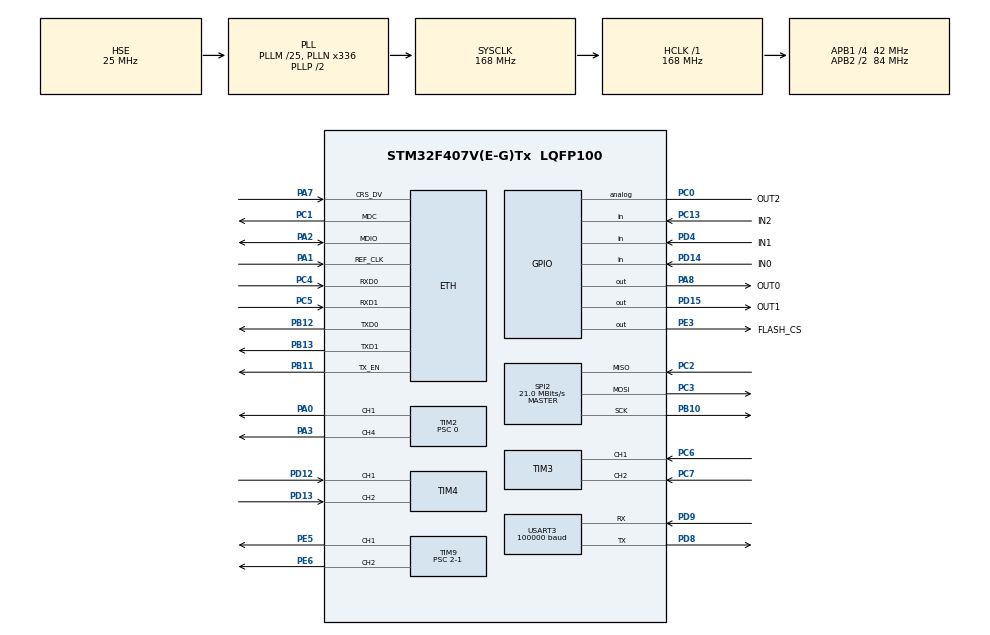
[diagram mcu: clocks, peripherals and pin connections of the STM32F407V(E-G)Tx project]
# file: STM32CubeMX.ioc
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Dma.Request0=USART3_RX
Dma.USART3_RX.0.Direction=DMA_PERIPH_TO_MEMORY
Dma.USART3_RX.0.FIFOMode=DMA_FIFOMODE_DISABLE
Dma.USART3_RX.0.Instance=DMA1_Stream1
Dma.USART3_RX.0.MemDataAlignment=DMA_MDATAALIGN_BYTE
Dma.USART3_RX.0.MemInc=DMA_MINC_ENABLE
Dma.USART3_RX.0.Mode=DMA_NORMAL
Dma.USART3_RX.0.PeriphDataAlignment=DMA_PDATAALIGN_BYTE
Dma.USART3_RX.0.PeriphInc=DMA_PINC_DISABLE
Dma.USART3_RX.0.Priority=DMA_PRIORITY_MEDIUM
ETH.MediaInterface=HAL_ETH_RMII_MODE
ETH.RxMode=ETH_RXINTERRUPT_MODE
Mcu.Family=STM32F4
Mcu.Name=STM32F407V(E-G)Tx
Mcu.Package=LQFP100
NVIC.DMA1_Stream1_IRQn=true\:5\:0\:true\:false\:true\:false\:true\:true
NVIC.ETH_IRQn=true\:7\:0\:true\:false\:true\:false\:true\:true
NVIC.PriorityGroup=NVIC_PRIORITYGROUP_4
NVIC.TIM3_IRQn=true\:4\:0\:true\:false\:true\:true\:true\:true
NVIC.TIM4_IRQn=true\:4\:0\:true\:false\:true\:true\:true\:true
NVIC.TIM7_IRQn=true\:4\:0\:true\:false\:true\:true\:true\:true
NVIC.TIM8_TRG_COM_TIM14_IRQn=true\:15\:0\:false\:false\:true\:false\:true\:true
NVIC.TimeBase=TIM8_TRG_COM_TIM14_IRQn
NVIC.TimeBaseIP=TIM14
NVIC.USART3_IRQn=true\:6\:0\:true\:false\:true\:true\:true\:true
PA0-WKUP.GPIO_Speed=GPIO_SPEED_FREQ_VERY_HIGH
PA0-WKUP.Signal=S_TIM2_CH1_ETR
PA1.Mode=RMII
PA1.Signal=ETH_REF_CLK
PA13.Mode=Serial_Wire
PA13.Signal=SYS_JTMS-SWDIO
PA14.Mode=Serial_Wire
PA14.Signal=SYS_JTCK-SWCLK
PA2.Mode=RMII
PA2.Signal=ETH_MDIO
PA3.GPIO_Speed=GPIO_SPEED_FREQ_VERY_HIGH
PA3.Signal=S_TIM2_CH4
PA7.Mode=RMII
PA7.Signal=ETH_CRS_DV
PA8.GPIO_Label=OUT0
PA8.Signal=GPIO_Output
PB10.Mode=Full_Duplex_Master
PB10.Signal=SPI2_SCK
PB11.Mode=RMII
PB11.Signal=ETH_TX_EN
PB12.Mode=RMII
PB12.Signal=ETH_TXD0
PB13.Mode=RMII
PB13.Signal=ETH_TXD1
PC0.GPIO_Label=OUT2
PC0.Signal=GPIO_Analog
PC1.Mode=RMII
PC1.Signal=ETH_MDC
PC13-ANTI_TAMP.GPIO_Label=IN2
PC13-ANTI_TAMP.Signal=GPIO_Input
PC14-OSC32_IN.Mode=LSE-External-Oscillator
PC14-OSC32_IN.Signal=RCC_OSC32_IN
PC15-OSC32_OUT.Mode=LSE-External-Oscillator
PC15-OSC32_OUT.Signal=RCC_OSC32_OUT
PC2.Mode=Full_Duplex_Master
PC2.Signal=SPI2_MISO
PC3.Mode=Full_Duplex_Master
PC3.Signal=SPI2_MOSI
PC4.Mode=RMII
PC4.Signal=ETH_RXD0
PC5.Mode=RMII
PC5.Signal=ETH_RXD1
PC6.GPIO_Speed=GPIO_SPEED_FREQ_HIGH
PC6.Signal=S_TIM3_CH1
PC7.GPIO_Speed=GPIO_SPEED_FREQ_HIGH
PC7.Signal=S_TIM3_CH2
PD12.Signal=S_TIM4_CH1
PD13.Signal=S_TIM4_CH2
PD14.GPIO_Label=IN0
PD14.Signal=GPIO_Input
PD15.GPIO_Label=OUT1
PD15.Signal=GPIO_Output
PD4.GPIO_Label=IN1
PD4.Signal=GPIO_Input
PD8.Mode=Asynchronous
PD8.Signal=USART3_TX
PD9.Mode=Asynchronous
PD9.Signal=USART3_RX
PE3.GPIO_Label=FLASH_CS
PE3.GPIO_Speed=GPIO_SPEED_FREQ_VERY_HIGH
PE3.Signal=GPIO_Output
PE5.GPIO_Speed=GPIO_SPEED_FREQ_VERY_HIGH
PE5.Signal=S_TIM9_CH1
PE6.GPIO_Speed=GPIO_SPEED_FREQ_VERY_HIGH
PE6.Signal=S_TIM9_CH2
PH0-OSC_IN.Mode=HSE-External-Oscillator
PH0-OSC_IN.Signal=RCC_OSC_IN
PH1-OSC_OUT.Mode=HSE-External-Oscillator
PH1-OSC_OUT.Signal=RCC_OSC_OUT
ProjectManager.HeapSize=0x200
ProjectManager.StackSize=0x200
ProjectManager.TargetToolchain=MDK-ARM V5.32
RCC.48MHZClocksFreq_Value=48000000
RCC.AHBFreq_Value=168000000
RCC.APB1CLKDivider=RCC_HCLK_DIV4
RCC.APB1Freq_Value=42000000
RCC.APB1TimFreq_Value=84000000
RCC.APB2CLKDivider=RCC_HCLK_DIV2
RCC.APB2Freq_Value=84000000
RCC.APB2TimFreq_Value=168000000
RCC.CortexFreq_Value=168000000
RCC.HCLKFreq_Value=168000000
RCC.HSE_VALUE=25000000
RCC.HSI_VALUE=16000000
RCC.PLLM=25
RCC.PLLN=336
RCC.PLLQ=7
RCC.PLLSourceVirtual=RCC_PLLSOURCE_HSE
RCC.SYSCLKFreq_VALUE=168000000
RCC.SYSCLKSource=RCC_SYSCLKSOURCE_PLLCLK
RCC.VCOOutputFreq_Value=336000000
SH.S_TIM2_CH1_ETR.0=TIM2_CH1,PWM Generation1 CH1
SH.S_TIM2_CH4.0=TIM2_CH4,PWM Generation4 CH4
SH.S_TIM3_CH1.0=TIM3_CH1,Encoder_Interface
SH.S_TIM3_CH2.0=TIM3_CH2,Encoder_Interface
SH.S_TIM4_CH1.0=TIM4_CH1,Encoder_Interface
SH.S_TIM4_CH2.0=TIM4_CH2,Encoder_Interface
SH.S_TIM9_CH1.0=TIM9_CH1,PWM Generation1 CH1
SH.S_TIM9_CH2.0=TIM9_CH2,PWM Generation2 CH2
SPI2.BaudRatePrescaler=SPI_BAUDRATEPRESCALER_2
SPI2.CalculateBaudRate=21.0 MBits/s
SPI2.Direction=SPI_DIRECTION_2LINES
SPI2.Mode=SPI_MODE_MASTER
SPI2.VirtualType=VM_MASTER
TIM2.Channel-PWM\ Generation1\ CH1=TIM_CHANNEL_1
TIM2.Channel-PWM\ Generation4\ CH4=TIM_CHANNEL_4
TIM2.Period=65535
TIM2.Prescaler=0
TIM3.EncoderMode=TIM_ENCODERMODE_TI12
TIM4.EncoderMode=TIM_ENCODERMODE_TI12
TIM4.IC1Polarity=TIM_ICPOLARITY_RISING
TIM7.Period=42000-1
TIM7.Prescaler=40-1
TIM9.Channel-PWM\ Generation1\ CH1=TIM_CHANNEL_1
TIM9.Channel-PWM\ Generation2\ CH2=TIM_CHANNEL_2
TIM9.Prescaler=2-1
USART3.BaudRate=100000
USART3.Mode=MODE_RX
USART3.Parity=PARITY_EVEN
USART3.StopBits=STOPBITS_2
USART3.VirtualMode=VM_ASYNC
USART3.WordLength=WORDLENGTH_9B
VP_SYS_VS_tim14.Mode=TIM14
VP_TIM7_VS_ClockSourceINT.Mode=Enable_Timer
board=custom

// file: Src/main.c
/* USER CODE BEGIN Header */
/**
  ******************************************************************************
  * @file           : main.c
  * @brief          : Main program body
  ******************************************************************************
  * @attention
  *
  * Copyright (c) 2025 STMicroelectronics.
  * All rights reserved.
  *
  * This software is licensed under terms that can be found in the LICENSE file
  * in the root directory of this software component.
  * If no LICENSE file comes with this software, it is provided AS-IS.
  *
  ******************************************************************************
  */
/* USER CODE END Header */
#include "main.h"
#include "string.h"

/* USER CODE BEGIN Includes */
#include "init.h"
/* USER CODE END Includes */

ETH_TxPacketConfig TxConfig;
ETH_DMADescTypeDef  DMARxDscrTab[ETH_RX_DESC_CNT]; /* Ethernet Rx DMA Descriptors */
ETH_DMADescTypeDef  DMATxDscrTab[ETH_TX_DESC_CNT]; /* Ethernet Tx DMA Descriptors */

ETH_HandleTypeDef heth;

SPI_HandleTypeDef hspi2;

TIM_HandleTypeDef htim2;
TIM_HandleTypeDef htim3;
TIM_HandleTypeDef htim4;
TIM_HandleTypeDef htim7;
TIM_HandleTypeDef htim9;

UART_HandleTypeDef huart3;
DMA_HandleTypeDef hdma_usart3_rx;

void SystemClock_Config(void);
static void MX_GPIO_Init(void);
static void MX_DMA_Init(void);
static void MX_ETH_Init(void);
static void MX_SPI2_Init(void);
static void MX_TIM3_Init(void);
static void MX_TIM9_Init(void);
static void MX_TIM2_Init(void);
static void MX_TIM4_Init(void);
static void MX_TIM7_Init(void);
static void MX_USART3_UART_Init(void);

int main(void)
{

  /* MCU Configuration--------------------------------------------------------*/

  /* Reset of all peripherals, Initializes the Flash interface and the Systick. */
  HAL_Init();

  /* Configure the system clock */
  SystemClock_Config();

  /* Initialize all configured peripherals */
  MX_GPIO_Init();
  MX_DMA_Init();
  MX_ETH_Init();
  MX_SPI2_Init();
  MX_TIM3_Init();
  MX_TIM9_Init();
  MX_TIM2_Init();
  MX_TIM4_Init();
  MX_TIM7_Init();
  MX_USART3_UART_Init();
  /* USER CODE BEGIN 2 */
	osKernelInitialize();
	System_Init();
	osKernelStart();
  /* USER CODE END 2 */

  /* Infinite loop */
  while (1)
  {

  }
}

void SystemClock_Config(void)
{
  RCC_OscInitTypeDef RCC_OscInitStruct = {0};
  RCC_ClkInitTypeDef RCC_ClkInitStruct = {0};

  /** Configure the main internal regulator output voltage
  */
  __HAL_RCC_PWR_CLK_ENABLE();
  __HAL_PWR_VOLTAGESCALING_CONFIG(PWR_REGULATOR_VOLTAGE_SCALE1);

  /** Initializes the RCC Oscillators according to the specified parameters
  * in the RCC_OscInitTypeDef structure.
  */
  RCC_OscInitStruct.OscillatorType = RCC_OSCILLATORTYPE_HSE;
  RCC_OscInitStruct.HSEState = RCC_HSE_ON;
  RCC_OscInitStruct.PLL.PLLState = RCC_PLL_ON;
  RCC_OscInitStruct.PLL.PLLSource = RCC_PLLSOURCE_HSE;
  RCC_OscInitStruct.PLL.PLLM = 25;
  RCC_OscInitStruct.PLL.PLLN = 336;
  RCC_OscInitStruct.PLL.PLLP = RCC_PLLP_DIV2;
  RCC_OscInitStruct.PLL.PLLQ = 7;
  if (HAL_RCC_OscConfig(&RCC_OscInitStruct) != HAL_OK)
  {
    Error_Handler();
  }

  /** Initializes the CPU, AHB and APB buses clocks
  */
  RCC_ClkInitStruct.ClockType = RCC_CLOCKTYPE_HCLK|RCC_CLOCKTYPE_SYSCLK
                              |RCC_CLOCKTYPE_PCLK1|RCC_CLOCKTYPE_PCLK2;
  RCC_ClkInitStruct.SYSCLKSource = RCC_SYSCLKSOURCE_PLLCLK;
  RCC_ClkInitStruct.AHBCLKDivider = RCC_SYSCLK_DIV1;
  RCC_ClkInitStruct.APB1CLKDivider = RCC_HCLK_DIV4;
  RCC_ClkInitStruct.APB2CLKDivider = RCC_HCLK_DIV2;

  if (HAL_RCC_ClockConfig(&RCC_ClkInitStruct, FLASH_LATENCY_5) != HAL_OK)
  {
    Error_Handler();
  }
}

static void MX_ETH_Init(void)
{

   static uint8_t MACAddr[6];

  heth.Instance = ETH;
  MACAddr[0] = 0x00;
  MACAddr[1] = 0x80;
  MACAddr[2] = 0xE1;
  MACAddr[3] = 0x00;
  MACAddr[4] = 0x00;
  MACAddr[5] = 0x00;
  heth.Init.MACAddr = &MACAddr[0];
  heth.Init.MediaInterface = HAL_ETH_RMII_MODE;
  heth.Init.TxDesc = DMATxDscrTab;
  heth.Init.RxDesc = DMARxDscrTab;
  heth.Init.RxBuffLen = 1524;

  if (HAL_ETH_Init(&heth) != HAL_OK)
  {
    Error_Handler();
  }

  memset(&TxConfig, 0 , sizeof(ETH_TxPacketConfig));
  TxConfig.Attributes = ETH_TX_PACKETS_FEATURES_CSUM | ETH_TX_PACKETS_FEATURES_CRCPAD;
  TxConfig.ChecksumCtrl = ETH_CHECKSUM_IPHDR_PAYLOAD_INSERT_PHDR_CALC;
  TxConfig.CRCPadCtrl = ETH_CRC_PAD_INSERT;

}

static void MX_SPI2_Init(void)
{

  /* SPI2 parameter configuration*/
  hspi2.Instance = SPI2;
  hspi2.Init.Mode = SPI_MODE_MASTER;
  hspi2.Init.Direction = SPI_DIRECTION_2LINES;
  hspi2.Init.DataSize = SPI_DATASIZE_8BIT;
  hspi2.Init.CLKPolarity = SPI_POLARITY_LOW;
  hspi2.Init.CLKPhase = SPI_PHASE_1EDGE;
  hspi2.Init.NSS = SPI_NSS_SOFT;
  hspi2.Init.BaudRatePrescaler = SPI_BAUDRATEPRESCALER_2;
  hspi2.Init.FirstBit = SPI_FIRSTBIT_MSB;
  hspi2.Init.TIMode = SPI_TIMODE_DISABLE;
  hspi2.Init.CRCCalculation = SPI_CRCCALCULATION_DISABLE;
  hspi2.Init.CRCPolynomial = 10;
  if (HAL_SPI_Init(&hspi2) != HAL_OK)
  {
    Error_Handler();
  }

}

static void MX_TIM2_Init(void)
{

  TIM_MasterConfigTypeDef sMasterConfig = {0};
  TIM_OC_InitTypeDef sConfigOC = {0};

  htim2.Instance = TIM2;
  htim2.Init.Prescaler = 0;
  htim2.Init.CounterMode = TIM_COUNTERMODE_UP;
  htim2.Init.Period = 65535;
  htim2.Init.ClockDivision = TIM_CLOCKDIVISION_DIV1;
  htim2.Init.AutoReloadPreload = TIM_AUTORELOAD_PRELOAD_DISABLE;
  if (HAL_TIM_PWM_Init(&htim2) != HAL_OK)
  {
    Error_Handler();
  }
  sMasterConfig.MasterOutputTrigger = TIM_TRGO_RESET;
  sMasterConfig.MasterSlaveMode = TIM_MASTERSLAVEMODE_DISABLE;
  if (HAL_TIMEx_MasterConfigSynchronization(&htim2, &sMasterConfig) != HAL_OK)
  {
    Error_Handler();
  }
  sConfigOC.OCMode = TIM_OCMODE_PWM1;
  sConfigOC.Pulse = 0;
  sConfigOC.OCPolarity = TIM_OCPOLARITY_HIGH;
  sConfigOC.OCFastMode = TIM_OCFAST_DISABLE;
  if (HAL_TIM_PWM_ConfigChannel(&htim2, &sConfigOC, TIM_CHANNEL_1) != HAL_OK)
  {
    Error_Handler();
  }
  if (HAL_TIM_PWM_ConfigChannel(&htim2, &sConfigOC, TIM_CHANNEL_4) != HAL_OK)
  {
    Error_Handler();
  }
  HAL_TIM_MspPostInit(&htim2);

}

static void MX_TIM3_Init(void)
{

  TIM_Encoder_InitTypeDef sConfig = {0};
  TIM_MasterConfigTypeDef sMasterConfig = {0};

  htim3.Instance = TIM3;
  htim3.Init.Prescaler = 0;
  htim3.Init.CounterMode = TIM_COUNTERMODE_UP;
  htim3.Init.Period = 65535;
  htim3.Init.ClockDivision = TIM_CLOCKDIVISION_DIV1;
  htim3.Init.AutoReloadPreload = TIM_AUTORELOAD_PRELOAD_DISABLE;
  sConfig.EncoderMode = TIM_ENCODERMODE_TI12;
  sConfig.IC1Polarity = TIM_ICPOLARITY_RISING;
  sConfig.IC1Selection = TIM_ICSELECTION_DIRECTTI;
  sConfig.IC1Prescaler = TIM_ICPSC_DIV1;
  sConfig.IC1Filter = 0;
  sConfig.IC2Polarity = TIM_ICPOLARITY_RISING;
  sConfig.IC2Selection = TIM_ICSELECTION_DIRECTTI;
  sConfig.IC2Prescaler = TIM_ICPSC_DIV1;
  sConfig.IC2Filter = 0;
  if (HAL_TIM_Encoder_Init(&htim3, &sConfig) != HAL_OK)
  {
    Error_Handler();
  }
  sMasterConfig.MasterOutputTrigger = TIM_TRGO_RESET;
  sMasterConfig.MasterSlaveMode = TIM_MASTERSLAVEMODE_DISABLE;
  if (HAL_TIMEx_MasterConfigSynchronization(&htim3, &sMasterConfig) != HAL_OK)
  {
    Error_Handler();
  }

}

static void MX_TIM4_Init(void)
{

  TIM_Encoder_InitTypeDef sConfig = {0};
  TIM_MasterConfigTypeDef sMasterConfig = {0};

  htim4.Instance = TIM4;
  htim4.Init.Prescaler = 0;
  htim4.Init.CounterMode = TIM_COUNTERMODE_UP;
  htim4.Init.Period = 65535;
  htim4.Init.ClockDivision = TIM_CLOCKDIVISION_DIV1;
  htim4.Init.AutoReloadPreload = TIM_AUTORELOAD_PRELOAD_DISABLE;
  sConfig.EncoderMode = TIM_ENCODERMODE_TI12;
  sConfig.IC1Polarity = TIM_ICPOLARITY_RISING;
  sConfig.IC1Selection = TIM_ICSELECTION_DIRECTTI;
  sConfig.IC1Prescaler = TIM_ICPSC_DIV1;
  sConfig.IC1Filter = 0;
  sConfig.IC2Polarity = TIM_ICPOLARITY_RISING;
  sConfig.IC2Selection = TIM_ICSELECTION_DIRECTTI;
  sConfig.IC2Prescaler = TIM_ICPSC_DIV1;
  sConfig.IC2Filter = 0;
  if (HAL_TIM_Encoder_Init(&htim4, &sConfig) != HAL_OK)
  {
    Error_Handler();
  }
  sMasterConfig.MasterOutputTrigger = TIM_TRGO_RESET;
  sMasterConfig.MasterSlaveMode = TIM_MASTERSLAVEMODE_DISABLE;
  if (HAL_TIMEx_MasterConfigSynchronization(&htim4, &sMasterConfig) != HAL_OK)
  {
    Error_Handler();
  }

}

static void MX_TIM7_Init(void)
{

  TIM_MasterConfigTypeDef sMasterConfig = {0};

  htim7.Instance = TIM7;
  htim7.Init.Prescaler = 40-1;
  htim7.Init.CounterMode = TIM_COUNTERMODE_UP;
  htim7.Init.Period = 42000-1;
  htim7.Init.AutoReloadPreload = TIM_AUTORELOAD_PRELOAD_DISABLE;
  if (HAL_TIM_Base_Init(&htim7) != HAL_OK)
  {
    Error_Handler();
  }
  sMasterConfig.MasterOutputTrigger = TIM_TRGO_RESET;
  sMasterConfig.MasterSlaveMode = TIM_MASTERSLAVEMODE_DISABLE;
  if (HAL_TIMEx_MasterConfigSynchronization(&htim7, &sMasterConfig) != HAL_OK)
  {
    Error_Handler();
  }

}

static void MX_TIM9_Init(void)
{

  TIM_OC_InitTypeDef sConfigOC = {0};

  htim9.Instance = TIM9;
  htim9.Init.Prescaler = 2-1;
  htim9.Init.CounterMode = TIM_COUNTERMODE_UP;
  htim9.Init.Period = 65535;
  htim9.Init.ClockDivision = TIM_CLOCKDIVISION_DIV1;
  htim9.Init.AutoReloadPreload = TIM_AUTORELOAD_PRELOAD_DISABLE;
  if (HAL_TIM_PWM_Init(&htim9) != HAL_OK)
  {
    Error_Handler();
  }
  sConfigOC.OCMode = TIM_OCMODE_PWM1;
  sConfigOC.Pulse = 0;
  sConfigOC.OCPolarity = TIM_OCPOLARITY_HIGH;
  sConfigOC.OCFastMode = TIM_OCFAST_DISABLE;
  if (HAL_TIM_PWM_ConfigChannel(&htim9, &sConfigOC, TIM_CHANNEL_1) != HAL_OK)
  {
    Error_Handler();
  }
  if (HAL_TIM_PWM_ConfigChannel(&htim9, &sConfigOC, TIM_CHANNEL_2) != HAL_OK)
  {
    Error_Handler();
  }
  HAL_TIM_MspPostInit(&htim9);

}

static void MX_USART3_UART_Init(void)
{

  huart3.Instance = USART3;
  huart3.Init.BaudRate = 100000;
  huart3.Init.WordLength = UART_WORDLENGTH_9B;
  huart3.Init.StopBits = UART_STOPBITS_2;
  huart3.Init.Parity = UART_PARITY_EVEN;
  huart3.Init.Mode = UART_MODE_RX;
  huart3.Init.HwFlowCtl = UART_HWCONTROL_NONE;
  huart3.Init.OverSampling = UART_OVERSAMPLING_16;
  if (HAL_UART_Init(&huart3) != HAL_OK)
  {
    Error_Handler();
  }

}

static void MX_DMA_Init(void)
{

  /* DMA controller clock enable */
  __HAL_RCC_DMA1_CLK_ENABLE();

  /* DMA interrupt init */
  /* DMA1_Stream1_IRQn interrupt configuration */
  HAL_NVIC_SetPriority(DMA1_Stream1_IRQn, 5, 0);
  HAL_NVIC_EnableIRQ(DMA1_Stream1_IRQn);

}

static void MX_GPIO_Init(void)
{
  LL_GPIO_InitTypeDef GPIO_InitStruct = {0};

  /* GPIO Ports Clock Enable */
  LL_AHB1_GRP1_EnableClock(LL_AHB1_GRP1_PERIPH_GPIOE);
  LL_AHB1_GRP1_EnableClock(LL_AHB1_GRP1_PERIPH_GPIOC);
  LL_AHB1_GRP1_EnableClock(LL_AHB1_GRP1_PERIPH_GPIOH);
  LL_AHB1_GRP1_EnableClock(LL_AHB1_GRP1_PERIPH_GPIOA);
  LL_AHB1_GRP1_EnableClock(LL_AHB1_GRP1_PERIPH_GPIOB);
  LL_AHB1_GRP1_EnableClock(LL_AHB1_GRP1_PERIPH_GPIOD);

  /**/
  LL_GPIO_ResetOutputPin(FLASH_CS_GPIO_Port, FLASH_CS_Pin);

  /**/
  LL_GPIO_ResetOutputPin(OUT1_GPIO_Port, OUT1_Pin);

  /**/
  LL_GPIO_ResetOutputPin(OUT0_GPIO_Port, OUT0_Pin);

  /**/
  GPIO_InitStruct.Pin = FLASH_CS_Pin;
  GPIO_InitStruct.Mode = LL_GPIO_MODE_OUTPUT;
  GPIO_InitStruct.Speed = LL_GPIO_SPEED_FREQ_VERY_HIGH;
  GPIO_InitStruct.OutputType = LL_GPIO_OUTPUT_PUSHPULL;
  GPIO_InitStruct.Pull = LL_GPIO_PULL_NO;
  LL_GPIO_Init(FLASH_CS_GPIO_Port, &GPIO_InitStruct);

  /**/
  GPIO_InitStruct.Pin = IN2_Pin;
  GPIO_InitStruct.Mode = LL_GPIO_MODE_INPUT;
  GPIO_InitStruct.Pull = LL_GPIO_PULL_NO;
  LL_GPIO_Init(IN2_GPIO_Port, &GPIO_InitStruct);

  /**/
  GPIO_InitStruct.Pin = OUT2_Pin;
  GPIO_InitStruct.Mode = LL_GPIO_MODE_ANALOG;
  GPIO_InitStruct.Pull = LL_GPIO_PULL_NO;
  LL_GPIO_Init(OUT2_GPIO_Port, &GPIO_InitStruct);

  /**/
  GPIO_InitStruct.Pin = IN0_Pin|IN1_Pin;
  GPIO_InitStruct.Mode = LL_GPIO_MODE_INPUT;
  GPIO_InitStruct.Pull = LL_GPIO_PULL_NO;
  LL_GPIO_Init(GPIOD, &GPIO_InitStruct);

  /**/
  GPIO_InitStruct.Pin = OUT1_Pin;
  GPIO_InitStruct.Mode = LL_GPIO_MODE_OUTPUT;
  GPIO_InitStruct.Speed = LL_GPIO_SPEED_FREQ_LOW;
  GPIO_InitStruct.OutputType = LL_GPIO_OUTPUT_PUSHPULL;
  GPIO_InitStruct.Pull = LL_GPIO_PULL_NO;
  LL_GPIO_Init(OUT1_GPIO_Port, &GPIO_InitStruct);

  /**/
  GPIO_InitStruct.Pin = OUT0_Pin;
  GPIO_InitStruct.Mode = LL_GPIO_MODE_OUTPUT;
  GPIO_InitStruct.Speed = LL_GPIO_SPEED_FREQ_LOW;
  GPIO_InitStruct.OutputType = LL_GPIO_OUTPUT_PUSHPULL;
  GPIO_InitStruct.Pull = LL_GPIO_PULL_NO;
  LL_GPIO_Init(OUT0_GPIO_Port, &GPIO_InitStruct);

}

void HAL_TIM_PeriodElapsedCallback(TIM_HandleTypeDef *htim)
{
  if (htim->Instance == TIM14)
  {
    HAL_IncTick();
  }
}

void Error_Handler(void)
{
  __disable_irq();
  while (1)
  {
  }
}
